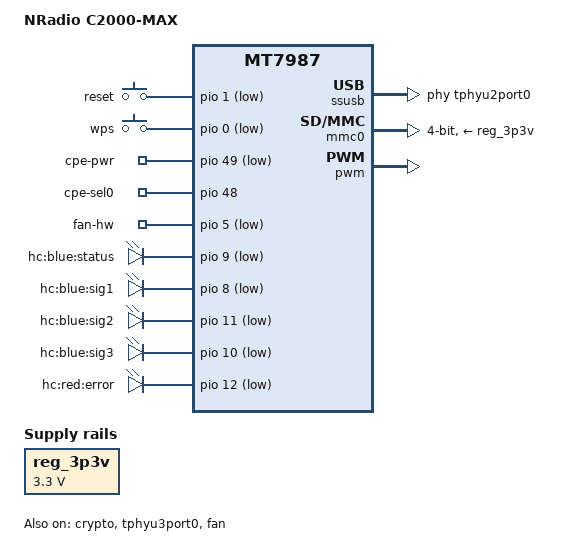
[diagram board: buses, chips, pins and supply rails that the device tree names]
/dts-v1/;
/* SPDX-License-Identifier: (GPL-2.0-only OR MIT) */

#include "mt7987a.dtsi"
#include <dt-bindings/input/input.h>

/ {
	model = "NRadio C2000-MAX";
	compatible = "nradio,c2000-max", "mediatek,mt7987";

	chosen {
		bootargs = "console=ttyS0,115200n1 loglevel=8 \
			    earlycon=uart8250,mmio32,0x11000000 \
			    pci=pcie_bus_perf \
			    root=PARTLABEL=rootfs rootwait \
			    rootfstype=squashfs,f2fs";
	};

	aliases {
		led-boot = &led_status;
		led-failsafe = &led_error;
		led-running = &led_status;
		led-upgrade = &led_status;
	};

	reg_3p3v: regulator-3p3v {
		compatible = "regulator-fixed";
		regulator-name = "fixed-3.3V";
		regulator-min-microvolt = <3300000>;
		regulator-max-microvolt = <3300000>;
		regulator-boot-on;
		regulator-always-on;
	};

	gpio-keys {
		compatible = "gpio-keys";

		reset {
			label = "reset";
			linux,code = <KEY_RESTART>;
			gpios = <&pio 1 GPIO_ACTIVE_LOW>;
			debounce-interval = <10>;
		};

		wps {
			label = "wps";
			linux,code = <KEY_WPS_BUTTON>;
			gpios = <&pio 0 GPIO_ACTIVE_LOW>;
			debounce-interval = <10>;
		};
	};

	gpio-export {
		compatible = "gpio-export";
		#size-cells = <0>;

		cpepower {
			gpio-export,name = "cpe-pwr";
			gpio-export,output = <0>;
			gpios = <&pio 49 GPIO_ACTIVE_LOW>;
		};

		cpesel0 {
			gpio-export,name = "cpe-sel0";
			gpio-export,output = <1>;
			gpios = <&pio 48 GPIO_ACTIVE_HIGH>;
		};

		fanpower {
			gpio-export,name = "fan-hw";
			gpio-export,output = <0>;
			gpios = <&pio 5 GPIO_ACTIVE_LOW>;
		};
	};

	gpio-leds {
		compatible = "gpio-leds";

		led_status: status {
			label = "hc:blue:status";
			gpios = <&pio 9 GPIO_ACTIVE_LOW>;
		};

		sig1 {
			label = "hc:blue:sig1";
			gpios = <&pio 8 GPIO_ACTIVE_LOW>;
		};

		sig2 {
			label = "hc:blue:sig2";
			gpios = <&pio 11 GPIO_ACTIVE_LOW>;
		};

		sig3 {
			label = "hc:blue:sig3";
			gpios = <&pio 10 GPIO_ACTIVE_LOW>;
		};

		led_error: error {
			label = "hc:red:error";
			gpios = <&pio 12 GPIO_ACTIVE_LOW>;
		};
	};
};

/* --- Network: override gmac1 mac-type for C2000-MAX --- */
&gmac1 {
	mac-type = "xgdm";
};

/* --- HNAT: C2000-MAX specific interface mapping --- */
&hnat {
	mtketh-wan = "eth0";
	mtketh-lan = "eth1";
	mtketh-lan2 = "hnat";
	mtketh-ppd = "hnat";
	mtketh-max-gmac = <3>;
	mtketh-ppe-num = <2>;
	ext-devices-prefix = "usb", "wwan", "rmnet", "eth2", "eth3";
};

/* --- Enable crypto engine --- */
&crypto {
	status = "okay";
};

/* --- USB 3.0 configuration --- */
&tphyu3port0 {
	status = "okay";
};

&ssusb {
	mediatek,u3p-dis-msk = <0>;
	phys = <&tphyu2port0 PHY_TYPE_USB2>,
	       <&tphyu3port0 PHY_TYPE_USB3>;
};

/* --- Disable spi1: MSDC and spi1 share pins on MT7987 --- */
&spi1 {
	status = "disabled";
};

/* --- SD card (eMMC controller in SD mode) --- */
&mmc0 {
	pinctrl-names = "default", "state_uhs";
	pinctrl-0 = <&sd_pins_default>;
	pinctrl-1 = <&sd_pins_uhs>;
	bus-width = <4>;
	max-frequency = <50000000>;
	cap-sd-highspeed;
	vmmc-supply = <&reg_3p3v>;
	vqmmc-supply = <&reg_3p3v>;
	no-mmc;
	no-sdio;
	status = "okay";
};

/* --- Fan (PWM channel 1, 40000ns period = 25kHz) --- */
&fan {
	pinctrl-names = "default";
	pwms = <&pwm 1 40000 0>;
	status = "okay";
};

&pwm {
	pinctrl-names = "default";
	pinctrl-0 = <&pwm_fan_pins>;
	status = "okay";
};
